# PIC18F47Q10 register map
Vendor: Microchip
Registers are 8-bit, read-write, reset 0x0 unless marked. A register's access mark holds for its fields unless they carry their own. Addresses are absolute, and some are shared; only a register's first bit layout is shown; [hi:lo] are bit positions; {n}, {i} and the like mark numbered series.

## CONFIG — Configuration words, addresses in ProgramSpace
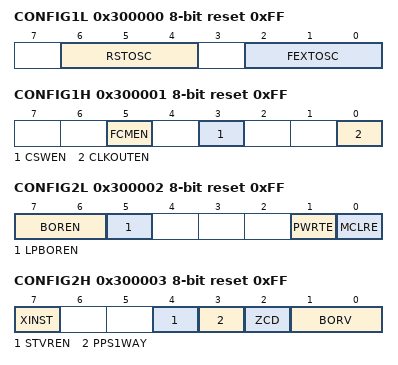
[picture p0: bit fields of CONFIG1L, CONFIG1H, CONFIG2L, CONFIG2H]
0x300000 CONFIG1L reset 0xFF
  [6:4] RSTOSC — Power-up default value for COSC bits
    0=HFINTOSC_64MHZ (HFINTOSC with HFFRQ = 64 MHz and CDIV = 1:1); 2=EXTOSC_4PLL (EXTOSC with 4x PLL, with EXTOSC operating per FEXTOSC bits); 4=SOSC (Secondary Oscillator); 5=LFINTOSC (Low-Frequency Oscillator); 6=HFINTOSC_1MHZ (HFINTOSC with HFFRQ = 4 MHz and CDIV = 4:1); 7=EXTOSC (EXTOSC operating per FEXTOSC bits (device manufacturing default))
  [2:0] FEXTOSC — External Oscillator mode Selection bits
    0=LP (LP (crystal oscillator) optimized for 32.768 kHz; PFM set to low power); 1=XT (XT (crystal oscillator) above 100 kHz, below 8 MHz; PFM set to medium power); 2=HS (HS (crystal oscillator) above 8 MHz; PFM set to high power); 4=OFF (Oscillator not enabled); 5=ECL (EC (external clock) below 100 kHz; PFM set to low power); 6=ECM (EC (external clock) for 500 kHz to 8 MHz; PFM set to medium power); 7=ECH (EC (external clock) above 8 MHz; PFM set to high power)
0x300001 CONFIG1H reset 0xFF
  [5] FCMEN — Fail-Safe Clock Monitor Enable bit
    0=OFF (Fail-Safe Clock Monitor disabled); 1=ON (Fail-Safe Clock Monitor enabled)
  [3] CSWEN — Clock Switch Enable bit
    0=OFF (The NOSC and NDIV bits cannot be changed by user software); 1=ON (Writing to NOSC and NDIV is allowed)
  [0] CLKOUTEN — Clock Out Enable bit
    1=OFF (CLKOUT function is disabled); 0=ON (CLKOUT function is enabled)
0x300002 CONFIG2L reset 0xFF
  [7:6] BOREN — Brown-out Reset Enable bits
    3=SBORDIS (Brown-out Reset enabled , SBOREN bit is ignored); 2=NOSLP (Brown-out Reset enabled while running, disabled in Sleep; SBOREN is ignored); 1=ON (Brown-out Reset enabled according to SBOREN); 0=OFF (Brown-out Reset disabled)
  [5] LPBOREN — Low-power BOR enable bit
    1=OFF (Low power BOR is disabled); 0=ON (Low power BOR is enabled)
  [1] PWRTE — Power-up Timer Enable bit
    0=ON (Power up timer enabled); 1=OFF (Power up timer disabled)
  [0] MCLRE — Master Clear Enable bit
    1=EXTMCLR (MCLR pin (RE3) is MCLR); 0=INTMCLR (If LVP = 0, MCLR pin (RE3) is an input; If LVP =1, MCLR pin (RE3) is MCLR)
0x300003 CONFIG2H reset 0xFF
  [7] XINST — Extended Instruction Set Enable bit
    1=OFF (Extended Instruction Set and Indexed Addressing Mode disabled); 0=ON (Extended Instruction Set and Indexed Addressing Mode enabled)
  [4] STVREN — Stack Full/Underflow Reset Enable bit
    1=ON (Stack full/underflow will cause Reset); 0=OFF (Stack full/underflow will not cause Reset)
  [3] PPS1WAY — PPSLOCK bit One-Way Set Enable bit
    1=ON (PPSLOCK bit can be cleared and set only once; PPS registers remain locked after one clear/set cycle); 0=OFF (PPSLOCK bit can be set and cleared repeatedly (subject to the unlock sequence))
  [2] ZCD — ZCD Disable bit
    1=OFF (ZCD disabled. ZCD can be enabled by setting the ZCDSEN bit of ZCDCON); 0=ON (ZCD always enabled)
  [1:0] BORV — Brown Out Reset Voltage selection bits
    3=VBOR_190 (Brown-out Reset Voltage (VBOR) set to 1.90V); 2=VBOR_245 (Brown-out Reset Voltage (VBOR) set to 2.45V); 1=VBOR_270 (Brown-out Reset Voltage (VBOR) set to 2.70V); 0=VBOR_285 (Brown-out Reset Voltage (VBOR) set to 2.85V)
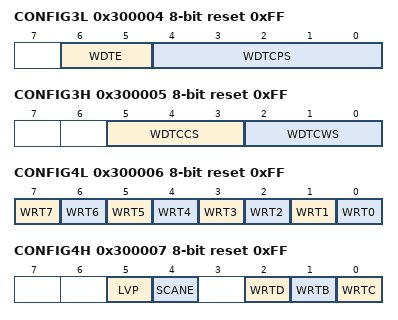
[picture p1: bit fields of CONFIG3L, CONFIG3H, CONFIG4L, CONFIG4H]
0x300004 CONFIG3L reset 0xFF
  [6:5] WDTE — WDT operating mode
    0=OFF (WDT Disabled); 1=SWDTEN (WDT enabled/disabled by SWDTEN bit); 2=NSLEEP (WDT disabled in sleep, enabled when not in sleep); 3=ON (WDT always enabled)
  [4:0] WDTCPS — WDT Period Select bits
    0=Divider ratio 1:32; 1=Divider ratio 1:64; 2=Divider ratio 1:128; 3=Divider ratio 1:256; 4=Divider ratio 1:512; 5=Divider ratio 1:1024; 6=Divider ratio 1:2048; 7=Divider ratio 1:4096; 8=Divider ratio 1:8192; 9=Divider ratio 1:16384; 10=Divider ratio 1:32768; 11=Divider ratio 1:65536; 12=Divider ratio 1:131072; 13=Divider ratio 1:262144; 14=Divider ratio 1:524299; 15=Divider ratio 1:1048576; 16=Divider ratio 1:2097152; 17=Divider ratio 1:4194304; 18=Divider ratio 1:8388608; {v}=Divider ratio 1:32 (v=19..30); 31=Divider ratio 1:65536; software control of WDTPS
0x300005 CONFIG3H reset 0xFF
  [5:3] WDTCCS — WDT input clock selector
    1=HFINTOSC (WDT reference clock is the 31.25 kHz MFINTOSC output); 0=LFINTOSC (WDT reference clock is the 31.0 kHz LFINTOSC); 7=SC (Software Control)
  [2:0] WDTCWS — WDT Window Select bits
    0=window delay = 87.5 % of time; no software control; keyed access required; 1=window delay = 75 % of time; no software control; keyed access required; 2=window delay = 62.5 % of time; no software control; keyed access required; 3=window delay = 50 % of time; no software control; keyed access required; 4=window delay = 37.5 % of time; no software control; keyed access required; 5=window delay = 25 % of time; no software control; keyed access required; 6=window always open (100%); no software control; keyed access required; 7=window always open (100%); software control; keyed access not required
0x300006 CONFIG4L reset 0xFF
  [7] WRT7 — Write Protection Block 7
    1=OFF (Block 7 (01C000-01FFFFh) not write-protected); 0=ON (Block 7 (01C000-01FFFFh) write-protected)
  [6] WRT6 — Write Protection Block 6
    1=OFF (Block 6 (018000-01BFFFh) not write-protected); 0=ON (Block 6 (018000-01BFFFh) write-protected)
  [5] WRT5 — Write Protection Block 5
    1=OFF (Block 5 (014000-017FFFh) not write-protected); 0=ON (Block 5 (014000-017FFFh) write-protected)
  [4] WRT4 — Write Protection Block 4
    1=OFF (Block 4 (010000-013FFFh) not write-protected); 0=ON (Block 4 (010000-013FFFh) not write-protected)
  [3] WRT3 — Write Protection Block 3
    1=OFF (Block 3 (00C000-00FFFFh) not write-protected); 0=ON (Block 3 (00C000-00FFFFh) write-protected)
  [2] WRT2 — Write Protection Block 2
    1=OFF (Block 2 (008000-00BFFFh) not write-protected); 0=ON (Block 2 (008000-00BFFFh) write-protected)
  [1] WRT1 — Write Protection Block 1
    1=OFF (Block 1 (004000-007FFFh) not write-protected); 0=ON (Block 1 (004000-007FFFh) write-protected)
  [0] WRT0 — Write Protection Block 0
    1=OFF (Block 0 (000800-003FFFh) not write-protected); 0=ON (Block 0 (000800-003FFFh) write-protected)
0x300007 CONFIG4H reset 0xFF
  [5] LVP — Low Voltage Programming Enable bit
    0=OFF (HV on MCLR/VPP must be used for programming); 1=ON (Low voltage programming enabled. MCLR/VPP pin function is MCLR. MCLRE configuration bit is ignored)
  [4] SCANE — Scanner Enable bit
    0=OFF (Scanner module is NOT available for use, SCANMD bit is ignored); 1=ON (Scanner module is available for use, SCANMD bit can control the module)
  [2] WRTD — Data EEPROM Write Protection bit
    1=OFF (Data EEPROM not write-protected); 0=ON (Data EEPROM write-protected)
  [1] WRTB — Boot Block Write Protection bit
    1=OFF (Boot Block (000000-0007FFh) not write-protected); 0=ON (Boot Block (000000-0007FFh) write-protected)
  [0] WRTC — Configuration Register Write Protection bit
    1=OFF (Configuration registers (300000-30000Bh) not write-protected); 0=ON (Configuration registers (300000-30000Bh) write-protected)
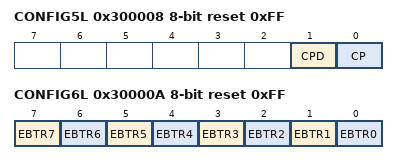
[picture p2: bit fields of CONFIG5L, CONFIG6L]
0x300008 CONFIG5L reset 0xFF
  [1] CPD — DataNVM Memory Code Protection bit
    1=OFF (DataNVM code protection disabled); 0=ON (DataNVM code protection enabled)
  [0] CP — UserNVM Program Memory Code Protection bit
    1=OFF (UserNVM code protection disabled); 0=ON (UserNVM code protection enabled)
0x300009 CONFIG5H access not given reset 0xFF
0x30000A CONFIG6L reset 0xFF
  [7] EBTR7 — Table Read Protection Block 7
    1=OFF (Block 7 (01C000-01FFFFh) not protected from table reads executed in other blocks); 0=ON (Block 7 (01C000-01FFFFh) protected from table reads executed in other blocks)
  [6] EBTR6 — Table Read Protection Block 6
    1=OFF (Block 6 (018000-01BFFFh) not protected from table reads executed in other blocks); 0=ON (Block 6 (018000-01BFFFh) protected from table reads executed in other blocks)
  [5] EBTR5 — Table Read Protection Block 5
    1=OFF (Block 5 (014000-017FFFh) not protected from table reads executed in other blocks); 0=ON (Block 5 (014000-017FFFh) protected from table reads executed in other blocks)
  [4] EBTR4 — Table Read Protection Block 4
    1=OFF (Block 4 (010000-013FFFh) not protected from table reads executed in other blocks); 0=ON (Block 4 (010000-013FFFh) protected from table reads executed in other blocks)
  [3] EBTR3 — Table Read Protection Block 3
    1=OFF (Block 3 (00C000-00FFFFh) not protected from table reads executed in other blocks); 0=ON (Block 3 (00C000-00FFFFh) protected from table reads executed in other blocks)
  [2] EBTR2 — Table Read Protection Block 2
    1=OFF (Block 2 (008000-00BFFFh) not protected from table reads executed in other blocks); 0=ON (Block 2 (008000-00BFFFh) protected from table reads executed in other blocks)
  [1] EBTR1 — Table Read Protection Block 1
    1=OFF (Block 1 (004000-007FFFh) not protected from table reads executed in other blocks); 0=ON (Block 1 (004000-007FFFh) protected from table reads executed in other blocks)
  [0] EBTR0 — Table Read Protection Block 0
    1=OFF (Block 0 (000800-003FFFh) not protected from table reads executed in other blocks); 0=ON (Block 0 (000800-003FFFh) protected from table reads executed in other blocks)
0x30000B CONFIG6H reset 0xFF
  [1] EBTRB — Boot Block Table Read Protection bit
    1=OFF (Boot Block (000000-0007FFh) not protected from table reads executed in other blocks); 0=ON (Boot Block (000000-0007FFh) protected from table reads executed in other blocks)
